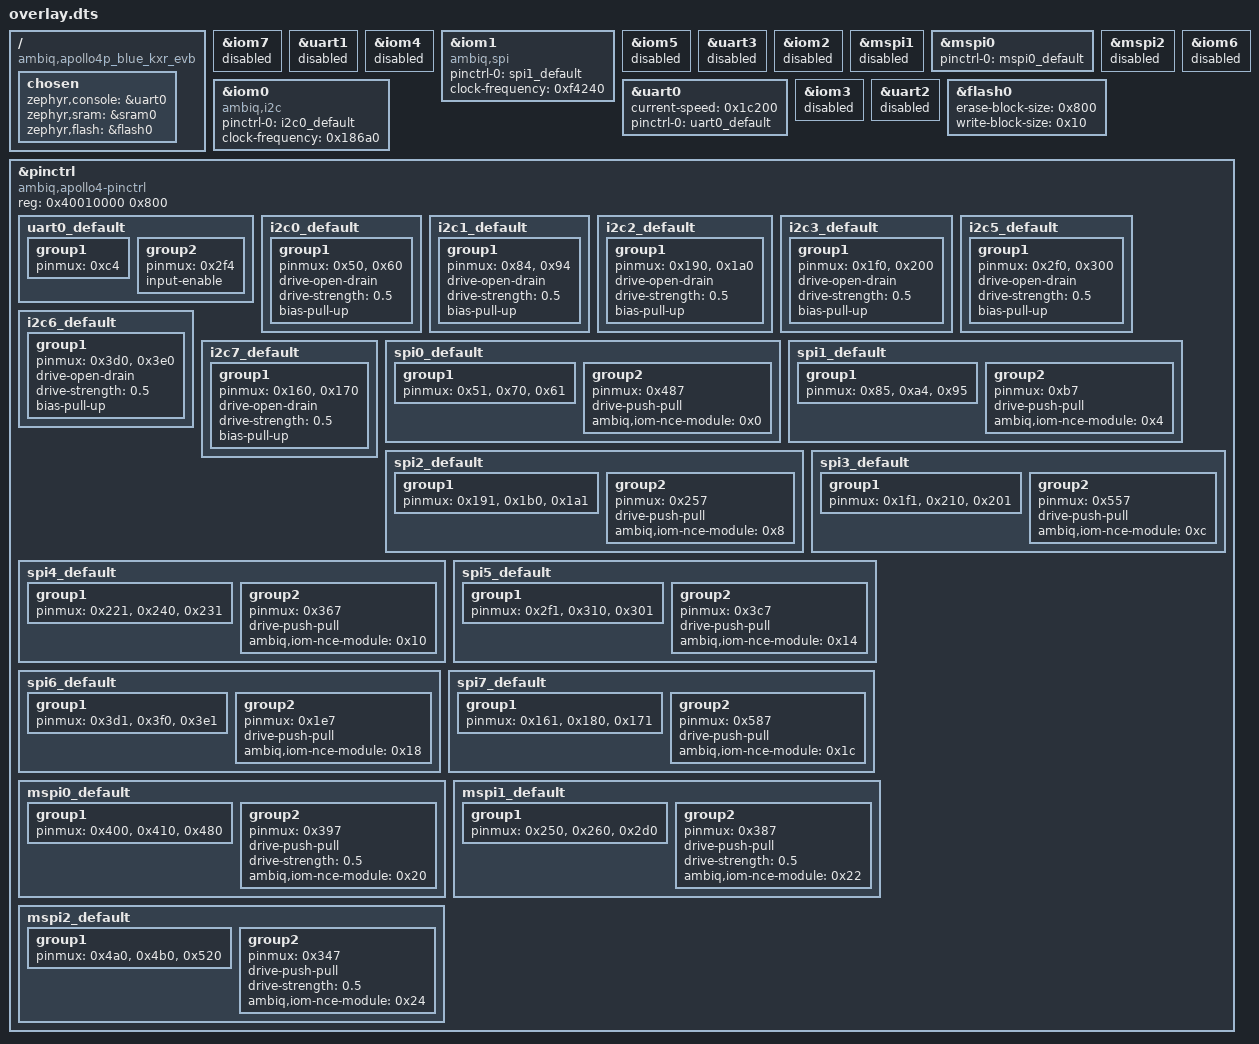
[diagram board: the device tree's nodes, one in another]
/ {
	compatible = "ambiq,apollo4p_blue_kxr_evb";
	chosen {
		zephyr,console = &uart0;
		zephyr,sram = &sram0;
		zephyr,flash = &flash0;
	};
};
&iom7{
	status = "disabled";
};
&uart1{
	status = "disabled";
};
&iom4{
	status = "disabled";
};
&iom1{
	status = "okay";
	compatible = "ambiq,spi";
	pinctrl-0 = < &spi1_default >;
	pinctrl-names = "default";
	clock-frequency = < 0xf4240 >;
};
&iom5{
	status = "disabled";
};
&uart3{
	status = "disabled";
};
&iom2{
	status = "disabled";
};
&mspi1{
	status = "disabled";
};
&mspi0{
	status = "okay";
	pinctrl-0 = < &mspi0_default >;
	pinctrl-names = "default";
};
&mspi2{
	status = "disabled";
};
&iom0{
	status = "okay";
	compatible = "ambiq,i2c";
	pinctrl-0 = < &i2c0_default >;
	pinctrl-names = "default";
	clock-frequency = < 0x186a0 >;
};
&iom6{
	status = "disabled";
};
&uart0{
	status = "okay";
	current-speed = < 0x1c200 >;
	pinctrl-0 = < &uart0_default >;
	pinctrl-names = "default";
};
&iom3{
	status = "disabled";
};
&uart2{
	status = "disabled";
};
&flash0{
	erase-block-size = < 0x800 >;
	write-block-size = < 0x10 >;
};
&pinctrl{
	compatible = "ambiq,apollo4-pinctrl";
	reg = < 0x40010000 0x800 >;
	uart0_default: uart0_default {
		group1 {
			pinmux = < 0xc4 >;
		};
		group2 {
			pinmux = < 0x2f4 >;
			input-enable;
		};
	};
	i2c0_default: i2c0_default {
		group1 {
			pinmux = < 0x50 >, < 0x60 >;
			drive-open-drain;
			drive-strength = "0.5";
			bias-pull-up;
		};
	};
	i2c1_default: i2c1_default {
		group1 {
			pinmux = < 0x84 >, < 0x94 >;
			drive-open-drain;
			drive-strength = "0.5";
			bias-pull-up;
		};
	};
	i2c2_default: i2c2_default {
		group1 {
			pinmux = < 0x190 >, < 0x1a0 >;
			drive-open-drain;
			drive-strength = "0.5";
			bias-pull-up;
		};
	};
	i2c3_default: i2c3_default {
		group1 {
			pinmux = < 0x1f0 >, < 0x200 >;
			drive-open-drain;
			drive-strength = "0.5";
			bias-pull-up;
		};
	};
	i2c5_default: i2c5_default {
		group1 {
			pinmux = < 0x2f0 >, < 0x300 >;
			drive-open-drain;
			drive-strength = "0.5";
			bias-pull-up;
		};
	};
	i2c6_default: i2c6_default {
		group1 {
			pinmux = < 0x3d0 >, < 0x3e0 >;
			drive-open-drain;
			drive-strength = "0.5";
			bias-pull-up;
		};
	};
	i2c7_default: i2c7_default {
		group1 {
			pinmux = < 0x160 >, < 0x170 >;
			drive-open-drain;
			drive-strength = "0.5";
			bias-pull-up;
		};
	};
	spi0_default: spi0_default {
		group1 {
			pinmux = < 0x51 >, < 0x70 >, < 0x61 >;
		};
		group2 {
			pinmux = < 0x487 >;
			drive-push-pull;
			ambiq,iom-nce-module = < 0x0 >;
		};
	};
	spi1_default: spi1_default {
		group1 {
			pinmux = < 0x85 >, < 0xa4 >, < 0x95 >;
		};
		group2 {
			pinmux = < 0xb7 >;
			drive-push-pull;
			ambiq,iom-nce-module = < 0x4 >;
		};
	};
	spi2_default: spi2_default {
		group1 {
			pinmux = < 0x191 >, < 0x1b0 >, < 0x1a1 >;
		};
		group2 {
			pinmux = < 0x257 >;
			drive-push-pull;
			ambiq,iom-nce-module = < 0x8 >;
		};
	};
	spi3_default: spi3_default {
		group1 {
			pinmux = < 0x1f1 >, < 0x210 >, < 0x201 >;
		};
		group2 {
			pinmux = < 0x557 >;
			drive-push-pull;
			ambiq,iom-nce-module = < 0xc >;
		};
	};
	spi4_default: spi4_default {
		group1 {
			pinmux = < 0x221 >, < 0x240 >, < 0x231 >;
		};
		group2 {
			pinmux = < 0x367 >;
			drive-push-pull;
			ambiq,iom-nce-module = < 0x10 >;
		};
	};
	spi5_default: spi5_default {
		group1 {
			pinmux = < 0x2f1 >, < 0x310 >, < 0x301 >;
		};
		group2 {
			pinmux = < 0x3c7 >;
			drive-push-pull;
			ambiq,iom-nce-module = < 0x14 >;
		};
	};
	spi6_default: spi6_default {
		group1 {
			pinmux = < 0x3d1 >, < 0x3f0 >, < 0x3e1 >;
		};
		group2 {
			pinmux = < 0x1e7 >;
			drive-push-pull;
			ambiq,iom-nce-module = < 0x18 >;
		};
	};
	spi7_default: spi7_default {
		group1 {
			pinmux = < 0x161 >, < 0x180 >, < 0x171 >;
		};
		group2 {
			pinmux = < 0x587 >;
			drive-push-pull;
			ambiq,iom-nce-module = < 0x1c >;
		};
	};
	mspi0_default: mspi0_default {
		group1 {
			pinmux = < 0x400 >, < 0x410 >, < 0x480 >;
		};
		group2 {
			pinmux = < 0x397 >;
			drive-push-pull;
			drive-strength = "0.5";
			ambiq,iom-nce-module = < 0x20 >;
		};
	};
	mspi1_default: mspi1_default {
		group1 {
			pinmux = < 0x250 >, < 0x260 >, < 0x2d0 >;
		};
		group2 {
			pinmux = < 0x387 >;
			drive-push-pull;
			drive-strength = "0.5";
			ambiq,iom-nce-module = < 0x22 >;
		};
	};
	mspi2_default: mspi2_default {
		group1 {
			pinmux = < 0x4a0 >, < 0x4b0 >, < 0x520 >;
		};
		group2 {
			pinmux = < 0x347 >;
			drive-push-pull;
			drive-strength = "0.5";
			ambiq,iom-nce-module = < 0x24 >;
		};
	};
};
